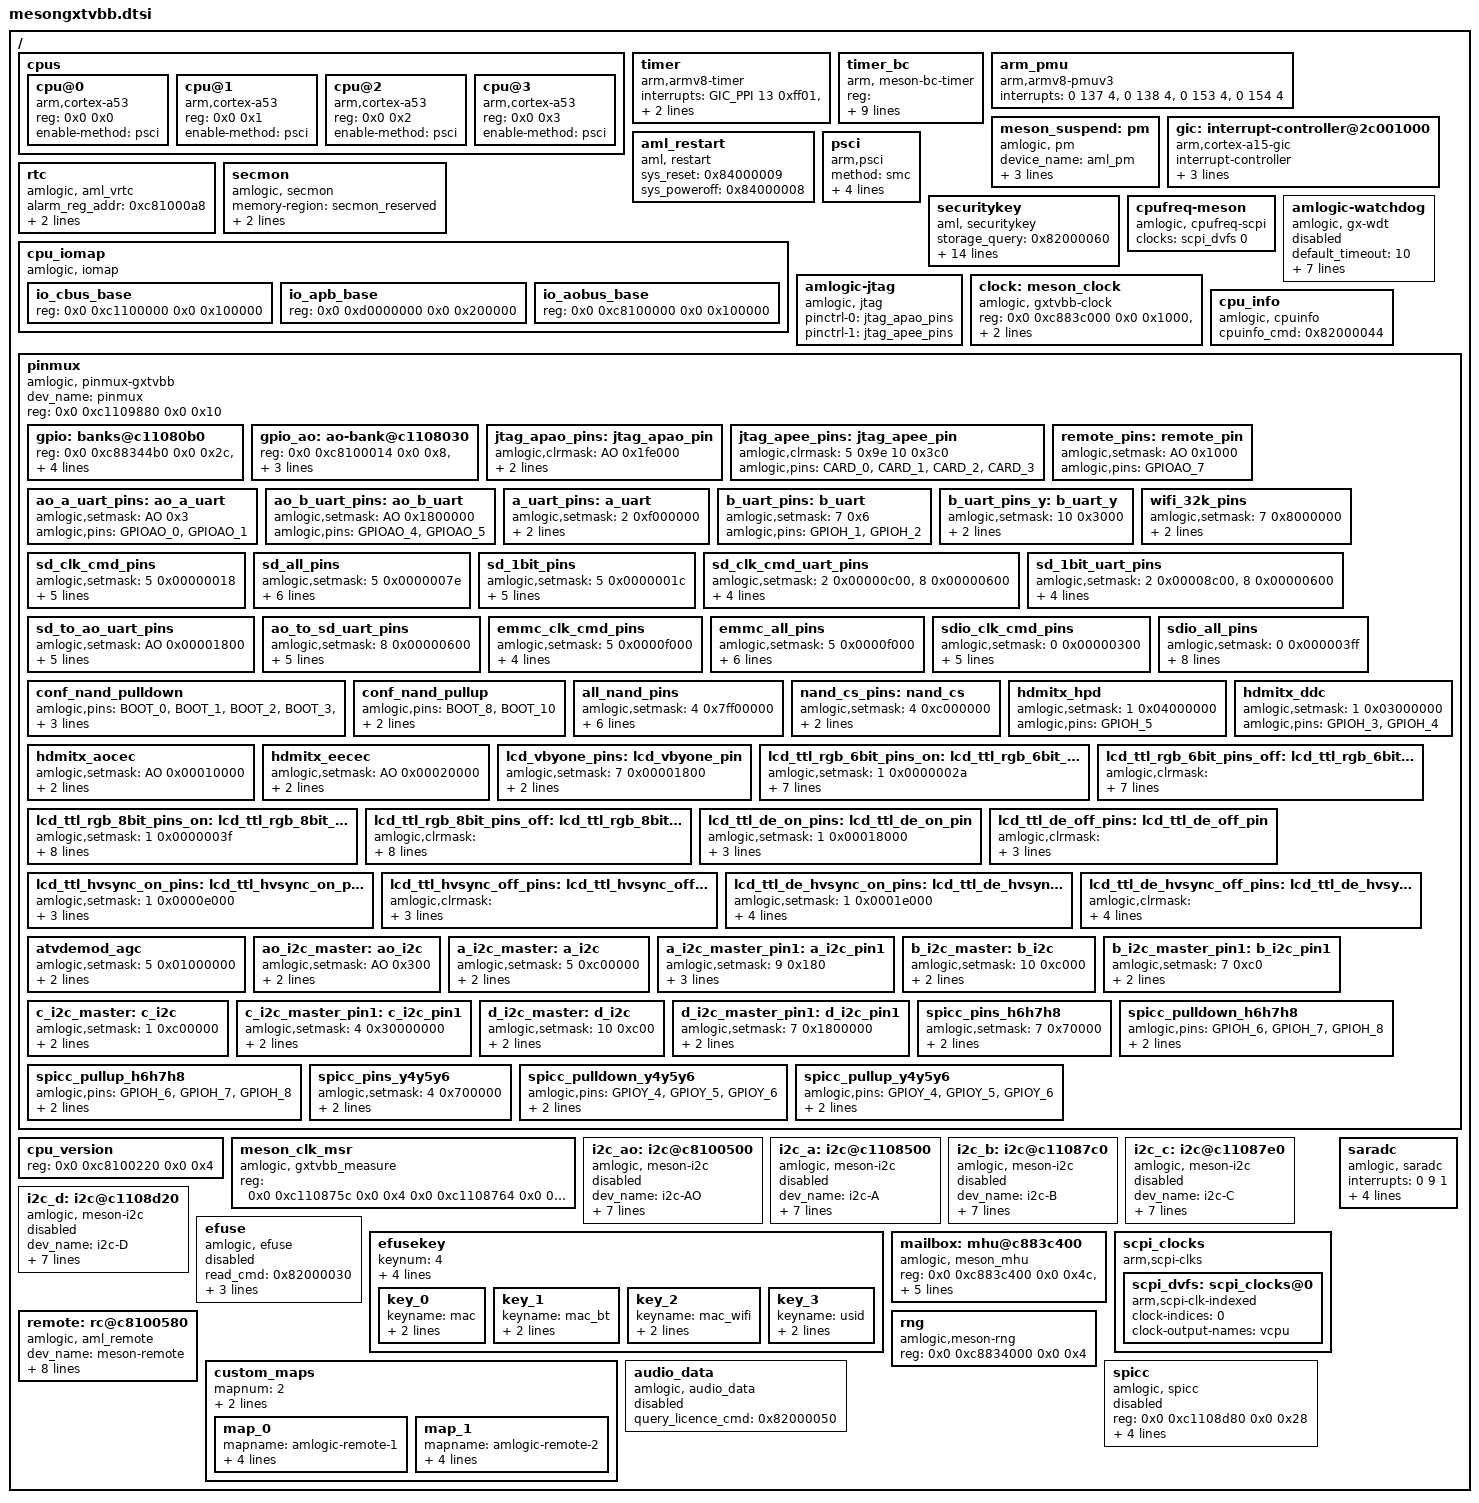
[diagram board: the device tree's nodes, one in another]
#include <dt-bindings/clock/gxtvbb.h>
#include <dt-bindings/gpio/gxtvbb.h>
#include <dt-bindings/gpio/gpio.h>
#include <dt-bindings/reset/aml_gxtvbb.h>
#include <dt-bindings/thermal/thermal.h>
#include <dt-bindings/interrupt-controller/arm-gic.h>
#include <dt-bindings/input/input.h>
#include <dt-bindings/input/meson_rc.h>
#include "mesongxtvbb-gpu-t83x.dtsi"
/ {
	cpus:cpus {
		#address-cells = <2>;
		#size-cells = <0>;
		#cooling-cells = <2>; /* min followed by max */

		cpu@0 {
			device_type = "cpu";
			compatible = "arm,cortex-a53","arm,armv8";
			reg = <0x0 0x0>;
			enable-method = "psci";
		};

		cpu@1 {
			device_type = "cpu";
			compatible = "arm,cortex-a53","arm,armv8";
			reg = <0x0 0x1>;
			enable-method = "psci";
		};
		cpu@2 {
			device_type = "cpu";
			compatible = "arm,cortex-a53","arm,armv8";
			reg = <0x0 0x2>;
			enable-method = "psci";
		};

		cpu@3 {
			device_type = "cpu";
			compatible = "arm,cortex-a53","arm,armv8";
			reg = <0x0 0x3>;
			enable-method = "psci";
		};


	};

	timer {
		compatible = "arm,armv8-timer";
		interrupts = <GIC_PPI 13 0xff01>,
				<GIC_PPI 14 0xff01>,
			        <GIC_PPI 11 0xff01>,
			        <GIC_PPI 10 0xff01>;
	};

	timer_bc {
		compatible = "arm, meson-bc-timer";
		reg=   <0x0 0xc1109990 0x0 0x4 0x0 0xc1109994 0x0 0x4>;
		timer_name = "Meson TimerF";
		clockevent-rating=<300>;
		clockevent-shift=<20>;
		clockevent-features=<0x03>;
		interrupts = <0 60 1>;
		bit_enable=<16>;
		bit_mode=<12>;
		bit_resolution=<0>;
	};
	arm_pmu {
		compatible = "arm,armv8-pmuv3";
		interrupts = <0 137 4>,
			     <0 138 4>,
			     <0 153 4>,
			     <0 154 4>;
	};
	meson_suspend:pm{
	           compatible = "amlogic, pm";
	           device_name = "aml_pm";
	           gxbaby-suspend;
	           reg = <0x0 0xc81000a8 0x0 0x4
	           		0x0 0xc810023c 0x0 0x4>;
	};

	gic: interrupt-controller@2c001000 {
		compatible = "arm,cortex-a15-gic", "arm,cortex-a9-gic";
		#interrupt-cells = <3>;
		#address-cells = <0>;
		interrupt-controller;
		reg = <0x0 0xc4301000 0 0x1000>,
		      <0x0 0xc4302000 0 0x0100>;
		interrupts = <GIC_PPI 9 0xf04>;
	};

	aml_restart{
		compatible = "aml, restart";
		sys_reset = <0x84000009>;
		sys_poweroff = <0x84000008>;
	};

	rtc{
		compatible = "amlogic, aml_vrtc";
		alarm_reg_addr = <0xc81000a8>;
		timer_e_addr = <0xc1109988>;
		init_date = "2015/01/01";
		status = "okay";
	};


	psci {
		compatible = "arm,psci";
		method = "smc";
		cpu_suspend = <0xC4000001>;
		cpu_off = <0x84000002>;
		cpu_on = <0xC4000003>;
		migrate = <0xC4000005>;
	};
	secmon {
		compatible = "amlogic, secmon";
		memory-region = <&secmon_reserved>;
		in_base_func = <0x82000020>;
		out_base_func = <0x82000021>;
	};
	securitykey {
		compatible = "aml, securitykey";
		storage_query = <0x82000060>;
		storage_read = <0x82000061>;
		storage_write = <0x82000062>;
		storage_tell = <0x82000063>;
		storage_verify = <0x82000064>;
		storage_status = <0x82000065>;
		storage_list = <0x82000067>;
		storage_remove = <0x82000068>;
		storage_in_func = <0x82000023>;
		storage_out_func = <0x82000024>;
		storage_block_func = <0x82000025>;
		storage_size_func = <0x82000027>;
		storage_set_enctype = <0x8200006A>;
		storage_get_enctype = <0x8200006B>;
		storage_version = <0x8200006C>;
	};
	cpu_iomap{
		compatible = "amlogic, iomap";
		#address-cells=<2>;
		#size-cells=<2>;
		ranges;
		io_cbus_base{
			reg = <0x0 0xc1100000 0x0 0x100000>;
		};
		io_apb_base{
			reg = <0x0 0xd0000000 0x0 0x200000>;
		};
		io_aobus_base{
			reg = <0x0 0xc8100000 0x0 0x100000>;
		};
	};
	cpufreq-meson {
		compatible = "amlogic, cpufreq-scpi";
		status = "okay";
		clocks = <&scpi_dvfs 0>;
		clock-names = "cpu_clk";
        };

	amlogic-watchdog{
		compatible = "amlogic, gx-wdt";
		status = "disable";
		default_timeout=<10>;
		reset_watchdog_method=<1>;//0:sysfs,1:kernel
		reset_watchdog_time=<2>;
		shutdown_timeout=<10>;
		firmware_timeout=<6>;
		suspend_timeout=<6>;
		reg = <0x0 0xc11098d0 0x0 0x10>;
		clocks = <&clock CLK_XTAL>;
	};
	amlogic-jtag {
		compatible = "amlogic, jtag";
		status = "okay";
		pinctrl-names = "jtag_apao_pins", "jtag_apee_pins";
		pinctrl-0 = <&jtag_apao_pins>;
		pinctrl-1 = <&jtag_apee_pins>;
	};
	clock: meson_clock {
		compatible = "amlogic, gxtvbb-clock";
		reg = <0x0 0xc883c000 0x0 0x1000>,   /* HIU BUS*/
		          <0x0 0xc8100000 0x0 0x1000>;   //AOBUS
		#clock-cells = <1>;
		#reset-cells = <1>;
		sys_max = <1536000000>;
	};

	cpu_info {
		compatible = "amlogic, cpuinfo";
		cpuinfo_cmd = <0x82000044>;
	};
	pinmux: pinmux{
		compatible = "amlogic, pinmux-gxtvbb";
		dev_name = "pinmux";
		#pinmux-cells=<2>;
		#address-cells = <2>;
		#size-cells = <2>;
		reg = <0x0 0xc1109880 0x0 0x10>;
		ranges;

		gpio: banks@c11080b0 {
			reg = <0x0 0xc88344b0 0x0 0x2c>,
                              <0x0 0xc88344e8 0x0 0x14>,
                              <0x0 0xc8834520 0x0 0x14>,
                              <0x0 0xc8834430 0x0 0x3c>;
			reg-names = "mux", "pull", "pull-enable", "gpio";
			gpio-controller;
			#gpio-cells = <2>;
		};

		gpio_ao: ao-bank@c1108030 {
			reg = <0x0 0xc8100014 0x0 0x8>,
                              <0x0 0xc810002c 0x0 0x4>,
                              <0x0 0xc8100024 0x0 0x8>;
			reg-names = "mux", "pull", "gpio";
			gpio-controller;
			#gpio-cells = <2>;
		};
		jtag_apao_pins:jtag_apao_pin{
			amlogic,clrmask = <AO 0x1fe000>;
			amlogic,pins = "GPIOAO_8","GPIOAO_9","GPIOAO_10","GPIOAO_11";
		};
		jtag_apee_pins:jtag_apee_pin{
			amlogic,clrmask = <5 0x9e 10 0x3c0>;
			amlogic,pins = "CARD_0","CARD_1","CARD_2","CARD_3";
		};
		remote_pins:remote_pin{
			amlogic,setmask = <AO 0x1000>;
			amlogic,pins = "GPIOAO_7";
		};
		ao_a_uart_pins:ao_a_uart{
			amlogic,setmask=<AO 0x3>;
			amlogic,pins="GPIOAO_0", "GPIOAO_1";
		};

		ao_b_uart_pins:ao_b_uart{
			amlogic,setmask=<AO 0x1800000>;
			amlogic,pins="GPIOAO_4", "GPIOAO_5";
		};

		a_uart_pins:a_uart{
			amlogic,setmask=<2 0xf000000>;
			amlogic,pins="GPIOX_12", "GPIOX_13", "GPIOX_14", "GPIOX_15";
		};

		b_uart_pins:b_uart{
			amlogic,setmask=<7 0x6>;
			amlogic,pins="GPIOH_1", "GPIOH_2";
		};

		b_uart_pins_y:b_uart_y{
			amlogic,setmask=<10 0x3000>;
			amlogic,clrmask=<10 0x1e0c000>;
			amlogic,pins="GPIOY_12", "GPIOY_13";
		};

		wifi_32k_pins:wifi_32k_pins{
			amlogic,setmask=<7 0x8000000>;
			amlogic,clrmask=<7 0x12020000>;
			amlogic,pins="GPIOH_7";
		};
		sd_clk_cmd_pins:sd_clk_cmd_pins{
			amlogic,setmask=<5 0x00000018>;
			amlogic,clrmask=<5 0x00000080 10 0x400>;
			amlogic,pins = "CARD_2","CARD_3"; /* CARD_2:CLK, CARD_3:CMD */
			amlogic,enable-output=<1>; /* 0:output, 1:input */
			amlogic,pullup=<1>;
			amlogic,pullupen=<1>;
		};

		sd_all_pins:sd_all_pins{
			amlogic,setmask=<5 0x0000007e>;
			amlogic,clrmask=<5 0x00000f80 10 0x400>;
			amlogic,pins="CARD_0","CARD_1","CARD_2","CARD_3","CARD_4","CARD_5";
			amlogic,enable-output=<1>; /* 0:output, 1:input */
			amlogic,pullup=<1>;
			amlogic,pullupen=<1>;
		};

		sd_1bit_pins:sd_1bit_pins{
			amlogic,setmask=<5 0x0000001c>;
			amlogic,clrmask=<5 0x00000080 10 0x400>;
			amlogic,pins = "CARD_1","CARD_2","CARD_3";
			amlogic,enable-output=<1>; /* 0:output, 1:input */
			amlogic,pullup=<1>;
			amlogic,pullupen=<1>;
		};

		sd_clk_cmd_uart_pins:sd_clk_cmd_uart_pins{
			amlogic,setmask=<2 0x00000c00>,
					<8 0x00000600>;
			amlogic,pins = "CARD_2","CARD_3"; /* CARD_2:CLK, CARD_3:CMD */
			amlogic,enable-output=<1>; /* 0:output, 1:input */
			amlogic,pullup=<1>;
			amlogic,pullupen=<1>;
		};

		sd_1bit_uart_pins:sd_1bit_uart_pins{
			amlogic,setmask=<2 0x00008c00>,
					<8 0x00000600>;
			amlogic,pins = "CARD_1","CARD_2","CARD_3";
			amlogic,enable-output=<1>; /* 0:output, 1:input */
			amlogic,pullup=<1>;
			amlogic,pullupen=<1>;
		};

		sd_to_ao_uart_pins:sd_to_ao_uart_pins{
			amlogic,setmask=<AO 0x00001800>;
			amlogic,clrmask=<8 0x00000600>;
			amlogic,pins = "GPIOAO_0","GPIOAO_1";
			amlogic,enable-output=<1>; /* 0:output, 1:input */
			amlogic,pullup=<1>;
			amlogic,pullupen=<1>;
		};

		ao_to_sd_uart_pins:ao_to_sd_uart_pins{
			amlogic,setmask=<8 0x00000600>;
			amlogic,clrmask=<AO 0x00001800>,
					<2 0x00003000>;
			amlogic,pins = "CARD_4","CARD_5";
			amlogic,enable-output=<1>; /* 0:output, 1:input */
			amlogic,pullup=<1>;
			amlogic,pullupen=<1>;
		};


		emmc_clk_cmd_pins:emmc_clk_cmd_pins{
			amlogic,setmask=<5 0x0000f000>;
			amlogic,pins = "BOOT_8","BOOT_10"; /** BOOT_10:CMD, BOOT_8:CLK */
			amlogic,enable-output=<1>; /** 0:output, 1:input */
			amlogic,pullup=<1>;
			amlogic,pullupen=<1>;
		};

		emmc_all_pins:emmc_all_pins{
			amlogic,setmask=<5 0x0000f000>;         /*sdhc c*/
			amlogic,pins = "BOOT_0","BOOT_1","BOOT_2","BOOT_3","BOOT_4",
				"BOOT_5","BOOT_6","BOOT_7","BOOT_8","BOOT_10";
			amlogic,enable-output=<1>; /** 0:output, 1:input */
			amlogic,pullup=<1>;
			amlogic,pullupen=<1>;
		};

		sdio_clk_cmd_pins:sdio_clk_cmd_pins{
			amlogic,setmask=<0 0x00000300>;
			amlogic,clrmask=<0 0x8c0300 1 0x804 2 0x40200>;
			amlogic,pins = "GPIOX_8","GPIOX_9"; /** GPIOX_5:CMD, GPIOX_4:CLK */
			amlogic,enable-output=<1>; /** 0:output, 1:input */
			amlogic,pullup=<1>;
			amlogic,pullupen=<1>;
		};

		sdio_all_pins:sdio_all_pins{
			amlogic,setmask=<0 0x000003ff>;
			amlogic,clrmask=<0 0x8ffc00 1 0x3ffc0c07 2 0x403ff>;
			amlogic,pins = "GPIOX_0","GPIOX_1","GPIOX_2","GPIOX_3","GPIOX_4","GPIOX_5",
							"GPIOX_6","GPIOX_7","GPIOX_8","GPIOX_9";
			amlogic,enable-output=<1>; /** 0:output, 1:input */
			amlogic,pullup=<1>;
			amlogic,pullupen=<1>;
		};

		/*aml_cam_gpio_pins: aml_cam_gpio_pins{
			amlogic,setmask=<2 0x3f0000>;
			amlogic,clrmask=<1 0x7030ff 3 0x37>;
			amlogic,pins = "GPIOY_0","GPIOY_1","GPIOY_2","GPIOY_3","GPIOY_4",
				"GPIOY_5","GPIOY_6","GPIOY_7","GPIOY_8",
				"GPIOY_9","GPIOY_10","GPIOY_15","GPIOY_16";
		};*/

		conf_nand_pulldown: conf_nand_pulldown{
			amlogic,pins = "BOOT_0","BOOT_1","BOOT_2","BOOT_3","BOOT_4",
					"BOOT_5","BOOT_6","BOOT_7","BOOT_15";
			amlogic,pullup=<0>;
			amlogic,pullupen=<1>;
		};

		conf_nand_pullup: conf_nand_pullup{
			amlogic,pins = "BOOT_8", "BOOT_10";
			amlogic,pullup=<1>;
			amlogic,pullupen=<1>;
		};

		all_nand_pins: all_nand_pins{
			amlogic,setmask=<4 0x7ff00000>;
			amlogic,clrmask=<0 0x80000
					4 0x800c0000
					5 0xf>;
			amlogic,pins = "BOOT_0","BOOT_1","BOOT_2","BOOT_3","BOOT_4",
					"BOOT_5","BOOT_6","BOOT_7","BOOT_8","BOOT_9",
					"BOOT_10","BOOT_11","BOOT_12","BOOT_13",
					"BOOT_14","BOOT_15","BOOT_16","BOOT_17";
			amlogic,enable-output=<1>;
		};

		nand_cs_pins: nand_cs{
			amlogic,setmask=<4 0xc000000>;
			amlogic,clrmask=<4 0x40000>;
			amlogic,pins = "BOOT_8","BOOT_9";
		};

		hdmitx_hpd: hdmitx_hpd {
			amlogic,setmask=<1 0x04000000>;
			amlogic,pins="GPIOH_5";
		};
		hdmitx_ddc: hdmitx_ddc {
			amlogic,setmask=<1 0x03000000>;
			amlogic,pins="GPIOH_3", "GPIOH_4";
		};
		hdmitx_aocec: hdmitx_aocec {
			amlogic,setmask=<AO  0x00010000>;
			amlogic,clrmask=<AO  0x00060000>;
			amlogic,pins="GPIOAO_9";
		};
		hdmitx_eecec: hdmitx_eecec {
			amlogic,setmask=<AO  0x00020000>;
			amlogic,clrmask=<AO  0x00050000>;
			amlogic,pins="GPIOAO_9";
		};
		lcd_vbyone_pins:lcd_vbyone_pin {
			amlogic,setmask = <7 0x00001800>;
			amlogic,clrmask = <7 0x00000606>;
			amlogic,pins = "GPIOH_1","GPIOH_2";
		};
		lcd_ttl_rgb_6bit_pins_on:lcd_ttl_rgb_6bit_on{
			amlogic,setmask=<1 0x0000002a>;
			amlogic,clrmask=<0 0xf0b3f0fc 1 0x003c0000 2 0x1fb8fcfc 3 0x2016ffcf>;
			amlogic,pins = "GPIOX_2","GPIOX_3","GPIOX_4","GPIOX_5","GPIOX_6","GPIOX_7", /* R2~R7 */
					"GPIOX_10","GPIOX_11","GPIOX_12","GPIOX_13","GPIOX_14","GPIOX_15", /* G2~G7 */
					"GPIOX_18","GPIOX_19","GPIOX_20","GPIOX_21","GPIOX_22","GPIOX_23"; /* B2~B7 */
		};

		lcd_ttl_rgb_6bit_pins_off:lcd_ttl_rgb_6bit_off{
			amlogic,clrmask=<0 0xf0b3f0fc 1 0x003c002a 2 0x1fb8fcfc 3 0x2016ffcf>;
			amlogic,pins = "GPIOX_2","GPIOX_3","GPIOX_4","GPIOX_5","GPIOX_6","GPIOX_7", /* R2~R7 */
					"GPIOX_10","GPIOX_11","GPIOX_12","GPIOX_13","GPIOX_14","GPIOX_15", /* G2~G7 */
					"GPIOX_18","GPIOX_19","GPIOX_20","GPIOX_21","GPIOX_22","GPIOX_23"; /* B2~B7 */
			amlogic,enable-output=<1>;
		};
		lcd_ttl_rgb_8bit_pins_on:lcd_ttl_rgb_8bit_on{
			amlogic,setmask=<1 0x0000003f>;
			amlogic,clrmask=<0 0xf0bfffff 1 0x00fc1c00 2 0x1fbfffff 3 0x2016ffff>;
			amlogic,pins = "GPIOX_0","GPIOX_1","GPIOX_2","GPIOX_3","GPIOX_4","GPIOX_5","GPIOX_6","GPIOX_7", /* R0~R7 */
					"GPIOX_8","GPIOX_9","GPIOX_10","GPIOX_11","GPIOX_12","GPIOX_13","GPIOX_14","GPIOX_15", /* G0~G7 */
					"GPIOX_16","GPIOX_17","GPIOX_18","GPIOX_19","GPIOX_20","GPIOX_21","GPIOX_22","GPIOX_23"; /* B0~B7 */
		};

		lcd_ttl_rgb_8bit_pins_off:lcd_ttl_rgb_8bit_off{
			amlogic,clrmask=<0 0xf0bfffff 1 0x00fc1c3f 2 0x1fbfffff 3 0x2016ffff>;
			amlogic,pins = "GPIOX_0","GPIOX_1","GPIOX_2","GPIOX_3","GPIOX_4","GPIOX_5","GPIOX_6","GPIOX_7", /* R0~R7 */
					"GPIOX_8","GPIOX_9","GPIOX_10","GPIOX_11","GPIOX_12","GPIOX_13","GPIOX_14","GPIOX_15", /* G0~G7 */
					"GPIOX_16","GPIOX_17","GPIOX_18","GPIOX_19","GPIOX_20","GPIOX_21","GPIOX_22","GPIOX_23"; /* B0~B7 */
			amlogic,enable-output=<1>;
		};
		lcd_ttl_de_on_pins:lcd_ttl_de_on_pin{ /* DE + clk */
			amlogic,setmask=<1 0x00018000>;
			amlogic,clrmask=<0 0x0c000000 1 0x00020000 3 0xdf000000>;
			amlogic,pins = "GPIOX_26","GPIOX_27";
		};

		lcd_ttl_de_off_pins:lcd_ttl_de_off_pin{ /* DE + clk */
			amlogic,clrmask=<0 0x0c000000 1 0x00038000 3 0xdf000000>;
			amlogic,pins = "GPIOX_26","GPIOX_27";
			amlogic,enable-output=<1>;
		};

		lcd_ttl_hvsync_on_pins:lcd_ttl_hvsync_on_pin{ /* hvsync + clk */
			amlogic,setmask=<1 0x0000e000>;
			amlogic,clrmask=<0 0x07000000 1 0x000000c0 3 0x6fc90000>;
			amlogic,pins = "GPIOX_24","GPIOX_25","GPIOX_26";
		};

		lcd_ttl_hvsync_off_pins:lcd_ttl_hvsync_off_pin{ /* hvsync + clk */
			amlogic,clrmask=<0 0x07000000 1 0x0000e0c0 3 0x6fc90000>;
			amlogic,pins = "GPIOX_24","GPIOX_25","GPIOX_26";
			amlogic,enable-output=<1>;
		};

		lcd_ttl_de_hvsync_on_pins:lcd_ttl_de_hvsync_on_pin{ /* DE + hvsync + clk */
			amlogic,setmask=<1 0x0001e000>;
			amlogic,clrmask=<0 0x0f000000 1 0x000200c0 3 0xffc90000>;
			amlogic,pins = "GPIOX_24","GPIOX_25","GPIOX_26","GPIOX_27";
		};

		lcd_ttl_de_hvsync_off_pins:lcd_ttl_de_hvsync_off_pin{ /* DE + hvsync + clk */
			amlogic,clrmask=<0 0x0f000000 1 0x0003e0c0 3 0xffc90000>;
			amlogic,pins = "GPIOX_24","GPIOX_25","GPIOX_26","GPIOX_27";
			amlogic,enable-output=<1>;
		};

		atvdemod_agc: atvdemod_agc {
			amlogic,setmask=<5  0x01000000>;
			amlogic,clrmask=<5  0x0e000000>;
			amlogic,pins="GPIOW_2";
		};

		/*gxtvbb i2c multiplex */
		/*I2C-AO*/
		ao_i2c_master:ao_i2c{
			amlogic,setmask=<AO 0x300>;
			amlogic,clrmask=<AO 0xcc0>;
			amlogic,pins="GPIOAO_4","GPIOAO_5";
		};
		/*I2C-A*/
		a_i2c_master:a_i2c{
			amlogic,setmask=<5 0xc00000>;
			amlogic,clrmask=<5 0x300000>;
			amlogic,pins="GPIOW_0","GPIOW_1";
		};
		a_i2c_master_pin1:a_i2c_pin1{
			amlogic,setmask=<9 0x180>;
			amlogic,clrmask=<8 0x6000000 9 0x30000678 10 0x1>;
			amlogic,pins="GPIOZ_17","GPIOZ_18";
		};
		/*I2C-B*/
		b_i2c_master:b_i2c{
			amlogic,setmask=<10 0xc000>;
			amlogic,clrmask=<10 0x1e03000>;
			amlogic,pins="GPIOY_12","GPIOY_13";
		};
		b_i2c_master_pin1:b_i2c_pin1{
			amlogic,setmask=<7 0xc0>;
			amlogic,clrmask=<7 0x180000>;
			amlogic,pins="GPIOH_3","GPIOH_4";
		};
		/*I2C-C*/
		c_i2c_master:c_i2c{
			amlogic,setmask=<1 0xc00000>;
			amlogic,clrmask=<0 0x800c03 1 0x300401 2 0x3>;
			amlogic,pins="GPIOX_0","GPIOX_1";
		};
		c_i2c_master_pin1:c_i2c_pin1{
			amlogic,setmask=<4 0x30000000>;
			amlogic,clrmask=<4 0xd801808 10 0x70000>;
			amlogic,pins="GPIOY_7","GPIOY_8";
		};
		/*I2C-D*/
		d_i2c_master:d_i2c{
			amlogic,setmask=<10 0xc00>;
			amlogic,clrmask=<4 0xc000c008>;
			amlogic,pins="GPIOY_10","GPIOY_11";
		};
		d_i2c_master_pin1:d_i2c_pin1{
			amlogic,setmask=<7 0x1800000>;
			amlogic,clrmask=<7 0x610028>;
			amlogic,pins="GPIOH_5","GPIOH_6";
		};
		spicc_pins_h6h7h8: spicc_pins_h6h7h8{
			amlogic,setmask=<7 0x70000>;
			amlogic,clrmask=<7 0x7f400028>;
			amlogic,pins="GPIOH_6","GPIOH_7","GPIOH_8";
		};
		spicc_pulldown_h6h7h8: spicc_pulldown_h6h7h8{
			amlogic,pins = "GPIOH_6","GPIOH_7","GPIOH_8";
			amlogic,pullup=<0>;
			amlogic,pullupen=<1>;
		};
		spicc_pullup_h6h7h8: spicc_pullup_h6h7h8{
			amlogic,pins = "GPIOH_6","GPIOH_7","GPIOH_8";
			amlogic,pullup=<1>;
			amlogic,pullupen=<1>;
		};

		spicc_pins_y4y5y6: spicc_pins_y4y5y6{
			amlogic,setmask=<4 0x700000>;
			amlogic,clrmask=<4 0x708>;
			amlogic,pins="GPIOY_4","GPIOY_5","GPIOY_6";
		};
		spicc_pulldown_y4y5y6: spicc_pulldown_y4y5y6{
			amlogic,pins="GPIOY_4","GPIOY_5","GPIOY_6";
			amlogic,pullup=<0>;
			amlogic,pullupen=<1>;
		};
		spicc_pullup_y4y5y6: spicc_pullup_y4y5y6{
			amlogic,pins="GPIOY_4","GPIOY_5","GPIOY_6";
			amlogic,pullup=<1>;
			amlogic,pullupen=<1>;
		};
	};
	cpu_version{
		reg=<0x0 0xc8100220 0x0 0x4>;
	};
	meson_clk_msr{
		compatible = "amlogic, gxtvbb_measure";
		reg = <0x0 0xc110875c 0x0 0x4
		       0x0 0xc1108764 0x0 0x4
		       0x0 0xc883c15c 0x0 0x4>;
	};

	i2c_ao: i2c@c8100500{ /*I2C-AO*/
		compatible = "amlogic, meson-i2c";
		dev_name = "i2c-AO";
		status = "disabled";
		reg = <0x0 0xc8100500 0x0 0x1d>;
		device_id = <0>;
		pinctrl-names="default";
		pinctrl-0=<&ao_i2c_master>;
		#address-cells = <1>;
		#size-cells = <0>;
		use_pio = <0>;
		master_i2c_speed = <300000>;
		clocks = <&clock CLK_81>;
		clock-names = "clk_i2c";
		resets = <&clock GCLK_IDX_I2C>;
	};
	i2c_a: i2c@c1108500{ /*I2C-A*/
		compatible = "amlogic, meson-i2c";
		dev_name = "i2c-A";
		status = "disabled";
		reg = <0x0 0xc1108500 0x0 0x20>;
		device_id = <1>;
		pinctrl-names="default";
		pinctrl-0=<&a_i2c_master>;
		#address-cells = <1>;
		#size-cells = <0>;
		use_pio = <0>;
		master_i2c_speed = <300000>;
		clocks = <&clock CLK_81>;
		clock-names = "clk_i2c";
		resets = <&clock GCLK_IDX_I2C>;
	};
	i2c_b: i2c@c11087c0{ /*I2C-B*/
		compatible = "amlogic, meson-i2c";
		dev_name = "i2c-B";
		status = "disabled";
		reg = <0x0 0xc11087c0 0x0 0x20>;
		device_id = <2>;
		pinctrl-names="default";
		pinctrl-0=<&b_i2c_master>;
		#address-cells = <1>;
		#size-cells = <0>;
		use_pio = <0>;
		master_i2c_speed = <300000>;
		clocks = <&clock CLK_81>;
		clock-names = "clk_i2c";
		resets = <&clock GCLK_IDX_I2C>;
	};
	i2c_c: i2c@c11087e0{ /*I2C-C*/
		compatible = "amlogic, meson-i2c";
		dev_name = "i2c-C";
		status = "disabled";
		reg = <0x0 0xc11087e0 0x0 0x20>;
		device_id = <3>;
		pinctrl-names="default";
		pinctrl-0=<&c_i2c_master>;
		#address-cells = <1>;
		#size-cells = <0>;
		use_pio = <0>;
		master_i2c_speed = <300000>;
		clocks = <&clock CLK_81>;
		clock-names = "clk_i2c";
		resets = <&clock GCLK_IDX_I2C>;
	};
	i2c_d: i2c@c1108d20{ /*I2C-D*/
		compatible = "amlogic, meson-i2c";
		dev_name = "i2c-D";
		status = "disabled";
		reg = <0x0 0xc1108d20 0x0 0x20>;
		device_id = <4>;
		pinctrl-names="default";
		pinctrl-0=<&d_i2c_master>;
		#address-cells = <1>;
		#size-cells = <0>;
		use_pio = <0>;
		master_i2c_speed = <300000>;
		clocks = <&clock CLK_81>;
		clock-names = "clk_i2c";
		resets = <&clock GCLK_IDX_I2C>;
	};

	efuse: efuse{
		compatible = "amlogic, efuse";
		read_cmd = <0x82000030>;
		write_cmd = <0x82000031>;
		get_max_cmd = <0x82000033>;
		key = <&efusekey>;
		status = "disabled";
	};
	efusekey:efusekey{
		keynum = <4>;
		key0 = <&key_0>;
		key1 = <&key_1>;
		key2 = <&key_2>;
		key3 = <&key_3>;
		key_0:key_0{
			keyname = "mac";
			offset = <0>;
			size = <6>;
		};
		key_1:key_1{
			keyname = "mac_bt";
			offset = <6>;
			size = <6>;
		};
		key_2:key_2{
			keyname = "mac_wifi";
			offset = <12>;
			size = <6>;
		};
		key_3:key_3{
			keyname = "usid";
			offset = <18>;
			size = <16>;
		};
	};

	mailbox: mhu@c883c400 {
		compatible = "amlogic, meson_mhu";
		status = "ok";
		reg = <0x0 0xc883c400 0x0 0x4c>,   /* MHU registers */
		      <0x0 0xc8013000 0x0 0x800>;   /* Payload area */
		interrupts = <0 209 IRQ_TYPE_EDGE_RISING>,   /* low priority interrupt */
			     <0 210 IRQ_TYPE_EDGE_RISING>;   /* high priority interrupt */
		#mbox-cells = <1>;
		mbox-names = "cpu_to_scp_low", "cpu_to_scp_high";
		mboxes = <&mailbox 0 &mailbox 1>;
	};
	scpi_clocks {
		compatible = "arm,scpi-clks";

		scpi_dvfs: scpi_clocks@0 {
			compatible = "arm,scpi-clk-indexed";
			#clock-cells = <1>;
			clock-indices = <0>;
			clock-output-names = "vcpu";
		};

	};

	remote:rc@c8100580 {
		compatible = "amlogic, aml_remote";
		dev_name = "meson-remote";
		reg = <0x0 0xc8100580 0x00 0x44>, /*Multi-format IR controller*/
			<0x0 0xc8100480 0x00 0x20>; /*Legacy IR controller*/
		status = "okay";
		protocol = <REMOTE_TYPE_NEC>;
		interrupts = <0 196 1>;
		pinctrl-names = "default";
		pinctrl-0 = <&remote_pins>;
		map = <&custom_maps>;
		release_delay = <80>;
		max_frame_time = <200>; /*set software decoder max frame time*/
	};

	custom_maps:custom_maps {
		mapnum = <2>;
		map0 = <&map_0>;
		map1 = <&map_1>;
		map_0: map_0{
			mapname = "amlogic-remote-1";
			customcode = <0xfb04>;
			size  = <44>;   /*keymap size*/
			keymap = <REMOTE_KEY(0x47, KEY_0)
				REMOTE_KEY(0x13, KEY_1)
				REMOTE_KEY(0x10, KEY_2)
				REMOTE_KEY(0x11, KEY_3)
				REMOTE_KEY(0x0F, KEY_4)
				REMOTE_KEY(0x0C, KEY_5)
				REMOTE_KEY(0x0D, KEY_6)
				REMOTE_KEY(0x0B, KEY_7)
				REMOTE_KEY(0x08, KEY_8)
				REMOTE_KEY(0x09, KEY_9)
				REMOTE_KEY(0x5C, KEY_RIGHTCTRL)
				REMOTE_KEY(0x51, KEY_F7)
				REMOTE_KEY(0x49, KEY_BACKSPACE)
				REMOTE_KEY(0x06, KEY_PROPS)
				REMOTE_KEY(0x14, KEY_UNDO)
				REMOTE_KEY(0x44, KEY_UP)
				REMOTE_KEY(0x1D, KEY_DOWN)
				REMOTE_KEY(0x1C, KEY_LEFT)
				REMOTE_KEY(0x48, KEY_RIGHT)
				REMOTE_KEY(0x53, KEY_LEFTMETA)
				REMOTE_KEY(0x45, KEY_PAGEUP)
				REMOTE_KEY(0x19, KEY_PAGEDOWN)
				REMOTE_KEY(0x16, KEY_HOME)//
				REMOTE_KEY(0x52, KEY_PAUSE)
				REMOTE_KEY(0x05, KEY_HANGEUL)
				REMOTE_KEY(0x59, KEY_HANJA)
				REMOTE_KEY(0x1b, KEY_SCALE)
				REMOTE_KEY(0x04, KEY_KPCOMMA)
				REMOTE_KEY(0x1A, KEY_POWER)
				REMOTE_KEY(0x0A, KEY_TAB)
				REMOTE_KEY(0x0e, KEY_MUTE)
				REMOTE_KEY(0x15, KEY_F5)
				REMOTE_KEY(0x1F, KEY_HOME)
				REMOTE_KEY(0x1e, KEY_FRONT)
				REMOTE_KEY(0x07, KEY_COPY)
				REMOTE_KEY(0x12, KEY_OPEN)
				REMOTE_KEY(0x54, KEY_PASTE)
				REMOTE_KEY(0x02, KEY_FIND)
				REMOTE_KEY(0x4f, KEY_A)
				REMOTE_KEY(0x42, KEY_B)
				REMOTE_KEY(0x5d, KEY_C)
				REMOTE_KEY(0x4c, KEY_D)
				REMOTE_KEY(0x58, KEY_CUT)
				REMOTE_KEY(0x55, KEY_CALC)>;
		};
		map_1: map_1{
			mapname = "amlogic-remote-2";
			customcode = <0xfe01>;
			size  = <53>;
			keymap = <REMOTE_KEY(0x01, KEY_1)
				REMOTE_KEY(0x02, KEY_2)
				REMOTE_KEY(0x03, KEY_3)
				REMOTE_KEY(0x04, KEY_4)
				REMOTE_KEY(0x05, KEY_5)
				REMOTE_KEY(0x06, KEY_6)
				REMOTE_KEY(0x07, KEY_7)
				REMOTE_KEY(0x08, KEY_8)
				REMOTE_KEY(0x09, KEY_9)
				REMOTE_KEY(0x0a, KEY_0)
				REMOTE_KEY(0x1F, KEY_FN_F1)
				REMOTE_KEY(0x15, KEY_MENU)
				REMOTE_KEY(0x16, KEY_TAB)
				REMOTE_KEY(0x0c, KEY_CHANNELUP)
				REMOTE_KEY(0x0d, KEY_CHANNELDOWN)
				REMOTE_KEY(0x0e, KEY_VOLUMEUP)
				REMOTE_KEY(0x0f, KEY_VOLUMEDOWN)
				REMOTE_KEY(0x11, KEY_HOME)
				REMOTE_KEY(0x1c, KEY_RIGHT)
				REMOTE_KEY(0x1b, KEY_LEFT)
				REMOTE_KEY(0x19, KEY_UP)
				REMOTE_KEY(0x1a, KEY_DOWN)
				REMOTE_KEY(0x1d, KEY_ENTER)
				REMOTE_KEY(0x17, KEY_MUTE)
				REMOTE_KEY(0x49, KEY_FINANCE)
				REMOTE_KEY(0x43, KEY_BACK)
				REMOTE_KEY(0x12, KEY_FN_F4)
				REMOTE_KEY(0x14, KEY_FN_F5)
				REMOTE_KEY(0x18, KEY_FN_F6)
				REMOTE_KEY(0x59, KEY_INFO)
				REMOTE_KEY(0x5a, KEY_STOPCD)
				REMOTE_KEY(0x10, KEY_POWER)
				REMOTE_KEY(0x42, KEY_PREVIOUSSONG)
				REMOTE_KEY(0x44, KEY_NEXTSONG)
				REMOTE_KEY(0x1e, KEY_REWIND)
				REMOTE_KEY(0x4b, KEY_FASTFORWARD)
				REMOTE_KEY(0x58, KEY_PLAYPAUSE)
				REMOTE_KEY(0x46, KEY_PROPS)
				REMOTE_KEY(0x40, KEY_UNDO)
				REMOTE_KEY(0x38, KEY_SCROLLLOCK)
				REMOTE_KEY(0x57, KEY_FN)
				REMOTE_KEY(0x5b, KEY_FN_ESC)
				REMOTE_KEY(0x54, KEY_RED)
				REMOTE_KEY(0x4c, KEY_GREEN)
				REMOTE_KEY(0x4e, KEY_YELLOW)
				REMOTE_KEY(0x55, KEY_BLUE)
				REMOTE_KEY(0x53, KEY_BLUETOOTH)
				REMOTE_KEY(0x52, KEY_WLAN)
				REMOTE_KEY(0x39, KEY_CAMERA)
				REMOTE_KEY(0x41, KEY_SOUND)
				REMOTE_KEY(0x0b, KEY_QUESTION)
				REMOTE_KEY(0x00, KEY_CHAT)
				REMOTE_KEY(0x13, KEY_SEARCH)>;
		};
 	};

	rng {
		compatible = "amlogic,meson-rng";
		reg = <0x0 0xc8834000 0x0 0x4>;
	};

	audio_data:audio_data {
		compatible = "amlogic, audio_data";
		query_licence_cmd = <0x82000050>;
		status = "disabled";
	};

	saradc: saradc {
		compatible = "amlogic, saradc";
		status = "okay";
		interrupts = <0 9 1>;
		interrupt-names = "saradc_int";
		clocks = <&clock CLK_XTAL>;
		clock-names = "saradc_clk";
		resets = <&clock GCLK_IDX_SARADC>;
		reg = <0x0 0xc8100600 0x0 0x30
					 0x0 0xc8100090 0x0 0x08>;
	};

	spicc:spicc{
		compatible = "amlogic, spicc";
		status = "disabled";
		reg = <0x0 0xc1108d80 0x0 0x28>;
		resets = <&clock GCLK_IDX_SPICC>;
		reset-names = "spicc_clk";
		clocks = <&clock CLK_81>;
		clock-names = "clk81";
		interrupts = <0 81 1>;
		device_id = <0>;
	};

};/* end of / */
